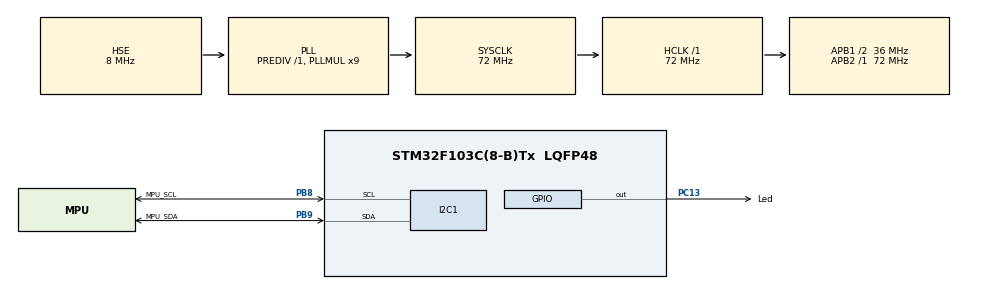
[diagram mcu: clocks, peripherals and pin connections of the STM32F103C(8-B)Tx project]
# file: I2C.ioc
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I2C1.I2C_Mode=I2C_Fast
Mcu.Family=STM32F1
Mcu.Name=STM32F103C(8-B)Tx
Mcu.Package=LQFP48
NVIC.PriorityGroup=NVIC_PRIORITYGROUP_4
PB8.GPIO_Label=MPU_SCL
PB8.GPIO_Mode=GPIO_MODE_AF_OD
PB8.Mode=I2C
PB8.Signal=I2C1_SCL
PB9.GPIO_Label=MPU_SDA
PB9.GPIO_Mode=GPIO_MODE_AF_OD
PB9.Mode=I2C
PB9.Signal=I2C1_SDA
PC13-TAMPER-RTC.GPIO_Label=Led
PC13-TAMPER-RTC.PinState=GPIO_PIN_RESET
PC13-TAMPER-RTC.Signal=GPIO_Output
PD0-OSC_IN.Mode=HSE-External-Oscillator
PD0-OSC_IN.Signal=RCC_OSC_IN
PD1-OSC_OUT.Mode=HSE-External-Oscillator
PD1-OSC_OUT.Signal=RCC_OSC_OUT
ProjectManager.HeapSize=0x200
ProjectManager.StackSize=0x400
ProjectManager.TargetToolchain=STM32CubeIDE
RCC.AHBFreq_Value=72000000
RCC.APB1CLKDivider=RCC_HCLK_DIV2
RCC.APB1Freq_Value=36000000
RCC.APB1TimFreq_Value=72000000
RCC.APB2Freq_Value=72000000
RCC.APB2TimFreq_Value=72000000
RCC.HCLKFreq_Value=72000000
RCC.PLLMUL=RCC_PLL_MUL9
RCC.PLLSourceVirtual=RCC_PLLSOURCE_HSE
RCC.SYSCLKFreq_VALUE=72000000
RCC.SYSCLKSource=RCC_SYSCLKSOURCE_PLLCLK
RCC.USBFreq_Value=48000000
RCC.USBPrescaler=RCC_USBCLKSOURCE_PLL_DIV1_5
VP_SYS_VS_ND.Mode=No_Debug
board=custom

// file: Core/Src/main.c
/* USER CODE BEGIN Header */
/**
  ******************************************************************************
  * @file           : main.c
  * @brief          : Main program body
  ******************************************************************************
  * @attention
  *
  * <h2><center>&copy; Copyright (c) 2020 STMicroelectronics.
  * All rights reserved.</center></h2>
  *
  * This software component is licensed by ST under BSD 3-Clause license,
  * the "License"; You may not use this file except in compliance with the
  * License. You may obtain a copy of the License at:
  *                        opensource.org/licenses/BSD-3-Clause
  *
  ******************************************************************************
  */
/* USER CODE END Header */

#include "main.h"

/* USER CODE BEGIN Includes */
#include  "stm32f1xx_hal_i2c.h"
/* USER CODE END Includes */

I2C_HandleTypeDef hi2c1;

/* USER CODE BEGIN PV */
const int motor_1_max=2150;//constante para la maxima posición del servomotor
const int motor_1_min=350;//constante para la minima posición del servomotor

char CDC_tx_buff[60];//El buffer para enviar los datos por usb
uint8_t CDC_tx_size;//tamaño de buffer
char CDC_rx_flag;//Variable que se modifica en el archivo  usbd_cdc_if.c
extern uint8_t CDC_Transmit_FS(uint8_t* Buf, uint16_t Len); //Función que se usa para enviar por usbd_cdc_if.c
//static const uint8_t MPU_ADDR = 0x68 << 1;
/* USER CODE END PV */

void SystemClock_Config(void);
static void MX_GPIO_Init(void);
static void MX_I2C1_Init(void);

int main(void)
{

  /* MCU Configuration--------------------------------------------------------*/

  /* Reset of all peripherals, Initializes the Flash interface and the Systick. */
  HAL_Init();

  /* Configure the system clock */
  SystemClock_Config();

  /* Initialize all configured peripherals */
  MX_GPIO_Init();
  MX_I2C1_Init();

  /* Infinite loop */
  /* USER CODE BEGIN WHILE */
  while (1)
  {
        HAL_Delay(2000);

        CDC_tx_size=sprintf(CDC_tx_buff,"Scanning I2C bus:\r\n");//Guarda en la variable CDC_tx_buff el string y el tamaño del string queda en CDC_size_buff
		CDC_Transmit_FS((uint8_t *)&CDC_tx_buff,CDC_tx_size);//Transmite por USB
		int i=1;
		for (i=1; i<128; i++)
		{
		  int result = HAL_I2C_IsDeviceReady(&hi2c1,i<<1,2, 2);
		  if (result != HAL_OK) // HAL_ERROR or HAL_BUSY or HAL_TIMEOUT
		  {
			//CDC_tx_size=sprintf(CDC_tx_buff,".");//Guarda en la variable CDC_tx_buff el string y el tamaño del string queda en CDC_size_buff
			CDC_Transmit_FS(CDC_tx_buff,CDC_tx_size);//Transmite por USB
		  }else{
			//CDC_tx_size=sprintf(CDC_tx_buff,"0x%X", i);//Guarda en la variable CDC_tx_buff el string y el tamaño del string queda en CDC_size_buff
			//CDC_Transmit_FS(CDC_tx_buff,CDC_tx_size);//Transmite por USB
			HAL_GPIO_TogglePin(Led_GPIO_Port, Led_Pin);
		  }
		}

    /* USER CODE END WHILE */

  }
}

void SystemClock_Config(void)
{
  RCC_OscInitTypeDef RCC_OscInitStruct = {0};
  RCC_ClkInitTypeDef RCC_ClkInitStruct = {0};

  /** Initializes the CPU, AHB and APB busses clocks
  */
  RCC_OscInitStruct.OscillatorType = RCC_OSCILLATORTYPE_HSE;
  RCC_OscInitStruct.HSEState = RCC_HSE_ON;
  RCC_OscInitStruct.HSEPredivValue = RCC_HSE_PREDIV_DIV1;
  RCC_OscInitStruct.HSIState = RCC_HSI_ON;
  RCC_OscInitStruct.PLL.PLLState = RCC_PLL_ON;
  RCC_OscInitStruct.PLL.PLLSource = RCC_PLLSOURCE_HSE;
  RCC_OscInitStruct.PLL.PLLMUL = RCC_PLL_MUL9;
  if (HAL_RCC_OscConfig(&RCC_OscInitStruct) != HAL_OK)
  {
    Error_Handler();
  }
  /** Initializes the CPU, AHB and APB busses clocks
  */
  RCC_ClkInitStruct.ClockType = RCC_CLOCKTYPE_HCLK|RCC_CLOCKTYPE_SYSCLK
                              |RCC_CLOCKTYPE_PCLK1|RCC_CLOCKTYPE_PCLK2;
  RCC_ClkInitStruct.SYSCLKSource = RCC_SYSCLKSOURCE_PLLCLK;
  RCC_ClkInitStruct.AHBCLKDivider = RCC_SYSCLK_DIV1;
  RCC_ClkInitStruct.APB1CLKDivider = RCC_HCLK_DIV2;
  RCC_ClkInitStruct.APB2CLKDivider = RCC_HCLK_DIV1;

  if (HAL_RCC_ClockConfig(&RCC_ClkInitStruct, FLASH_LATENCY_2) != HAL_OK)
  {
    Error_Handler();
  }
}

static void MX_I2C1_Init(void)
{

  /* USER CODE BEGIN I2C1_Init 0 */
	GPIO_InitTypeDef GPIO_InitStruct = {0};
	GPIO_InitStruct.Pin = MPU_SCL_Pin;
	GPIO_InitStruct.Mode = GPIO_MODE_AF_OD;
	GPIO_InitStruct.Speed = GPIO_SPEED_FREQ_HIGH;
	HAL_GPIO_Init(MPU_SCL_GPIO_Port, &GPIO_InitStruct);

	GPIO_InitStruct.Pin = MPU_SDA_Pin;
	GPIO_InitStruct.Mode = GPIO_MODE_AF_OD;
	GPIO_InitStruct.Speed = GPIO_SPEED_FREQ_HIGH;
	HAL_GPIO_Init(MPU_SDA_GPIO_Port, &GPIO_InitStruct);
  /* USER CODE END I2C1_Init 0 */

  hi2c1.Instance = I2C1;
  hi2c1.Init.ClockSpeed = 400000;
  hi2c1.Init.DutyCycle = I2C_DUTYCYCLE_2;
  hi2c1.Init.OwnAddress1 = 0;
  hi2c1.Init.AddressingMode = I2C_ADDRESSINGMODE_7BIT;
  hi2c1.Init.DualAddressMode = I2C_DUALADDRESS_DISABLE;
  hi2c1.Init.OwnAddress2 = 0;
  hi2c1.Init.GeneralCallMode = I2C_GENERALCALL_DISABLE;
  hi2c1.Init.NoStretchMode = I2C_NOSTRETCH_DISABLE;
  if (HAL_I2C_Init(&hi2c1) != HAL_OK)
  {
    Error_Handler();
  }

}

static void MX_GPIO_Init(void)
{
  GPIO_InitTypeDef GPIO_InitStruct = {0};

  /* GPIO Ports Clock Enable */
  __HAL_RCC_GPIOC_CLK_ENABLE();
  __HAL_RCC_GPIOD_CLK_ENABLE();
  __HAL_RCC_GPIOB_CLK_ENABLE();

  /*Configure GPIO pin Output Level */
  HAL_GPIO_WritePin(Led_GPIO_Port, Led_Pin, GPIO_PIN_RESET);

  /*Configure GPIO pin : Led_Pin */
  GPIO_InitStruct.Pin = Led_Pin;
  GPIO_InitStruct.Mode = GPIO_MODE_OUTPUT_PP;
  GPIO_InitStruct.Pull = GPIO_NOPULL;
  GPIO_InitStruct.Speed = GPIO_SPEED_FREQ_LOW;
  HAL_GPIO_Init(Led_GPIO_Port, &GPIO_InitStruct);

}

void Error_Handler(void)
{
  /* USER CODE BEGIN Error_Handler_Debug */
  /* User can add his own implementation to report the HAL error return state */
 if (HAL_I2C_Init(&hi2c1) != HAL_OK)
	  {

	  }
  /* USER CODE END Error_Handler_Debug */
}

/************************ (C) COPYRIGHT STMicroelectronics *****END OF FILE****/
